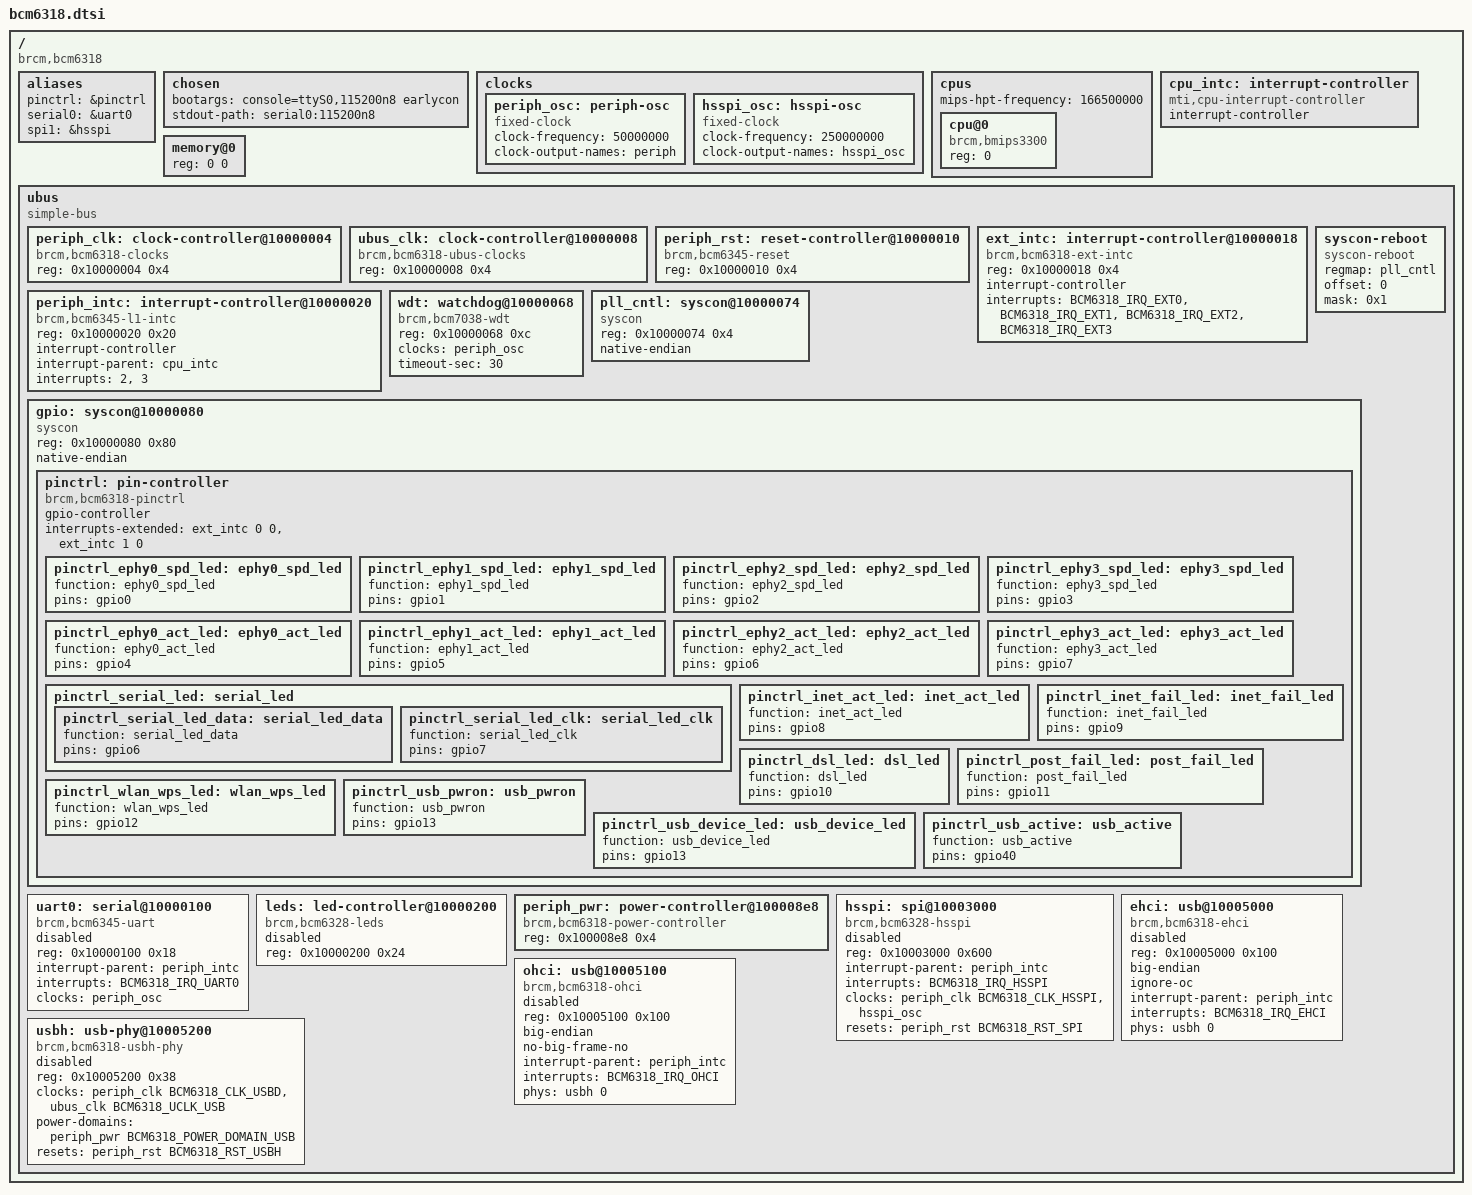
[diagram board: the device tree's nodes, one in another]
// SPDX-License-Identifier: GPL-2.0-or-later

/dts-v1/;

#include <dt-bindings/clock/bcm6318-clock.h>
#include <dt-bindings/gpio/gpio.h>
#include <dt-bindings/input/input.h>
#include <dt-bindings/interrupt-controller/bcm6318-interrupt-controller.h>
#include <dt-bindings/reset/bcm6318-reset.h>
#include <dt-bindings/soc/bcm6318-pm.h>

/ {
	#address-cells = <1>;
	#size-cells = <1>;
	compatible = "brcm,bcm6318";

	aliases {
		pinctrl = &pinctrl;
		serial0 = &uart0;
		spi1 = &hsspi;
	};

	chosen {
		bootargs = "console=ttyS0,115200n8 earlycon";
		stdout-path = "serial0:115200n8";
	};

	clocks {
		periph_osc: periph-osc {
			compatible = "fixed-clock";

			#clock-cells = <0>;

			clock-frequency = <50000000>;
			clock-output-names = "periph";
		};

		hsspi_osc: hsspi-osc {
			compatible = "fixed-clock";

			#clock-cells = <0>;

			clock-frequency = <250000000>;
			clock-output-names = "hsspi_osc";
		};
	};

	cpus {
		#address-cells = <1>;
		#size-cells = <0>;
		mips-hpt-frequency = <166500000>;

		cpu@0 {
			compatible = "brcm,bmips3300", "mips,mips4Kc";
			device_type = "cpu";
			reg = <0>;
		};
	};

	cpu_intc: interrupt-controller {
		#address-cells = <0>;
		compatible = "mti,cpu-interrupt-controller";

		interrupt-controller;
		#interrupt-cells = <1>;
	};

	memory@0 {
		device_type = "memory";
		reg = <0 0>;
	};

	ubus {
		#address-cells = <1>;
		#size-cells = <1>;

		compatible = "simple-bus";
		ranges;

		periph_clk: clock-controller@10000004 {
			compatible = "brcm,bcm6318-clocks";
			reg = <0x10000004 0x4>;
			#clock-cells = <1>;
		};

		ubus_clk: clock-controller@10000008 {
			compatible = "brcm,bcm6318-ubus-clocks";
			reg = <0x10000008 0x4>;
			#clock-cells = <1>;
		};

		periph_rst: reset-controller@10000010 {
			compatible = "brcm,bcm6345-reset";
			reg = <0x10000010 0x4>;
			#reset-cells = <1>;
		};

		ext_intc: interrupt-controller@10000018 {
			#address-cells = <1>;
			compatible = "brcm,bcm6318-ext-intc";
			reg = <0x10000018 0x4>;

			interrupt-controller;
			#interrupt-cells = <2>;

			interrupts = <BCM6318_IRQ_EXT0>,
				     <BCM6318_IRQ_EXT1>,
				     <BCM6318_IRQ_EXT2>,
				     <BCM6318_IRQ_EXT3>;
		};

		periph_intc: interrupt-controller@10000020 {
			#address-cells = <1>;
			compatible = "brcm,bcm6345-l1-intc";
			reg = <0x10000020 0x20>;

			interrupt-controller;
			#interrupt-cells = <1>;

			interrupt-parent = <&cpu_intc>;
			interrupts = <2>, <3>;
		};

		wdt: watchdog@10000068 {
			compatible = "brcm,bcm7038-wdt";
			reg = <0x10000068 0xc>;

			clocks = <&periph_osc>;

			timeout-sec = <30>;
		};

		pll_cntl: syscon@10000074 {
			compatible = "syscon";
			reg = <0x10000074 0x4>;
			native-endian;
		};

		syscon-reboot {
			compatible = "syscon-reboot";
			regmap = <&pll_cntl>;
			offset = <0>;
			mask = <0x1>;
		};

		gpio: syscon@10000080 {
			compatible = "syscon", "simple-mfd";
			reg = <0x10000080 0x80>;
			native-endian;

			pinctrl: pin-controller {
				compatible = "brcm,bcm6318-pinctrl";

				gpio-controller;
				#gpio-cells = <2>;

				interrupts-extended = <&ext_intc 0 0>,
						      <&ext_intc 1 0>;
				interrupt-names = "gpio33",
						  "gpio34";

				pinctrl_ephy0_spd_led: ephy0_spd_led {
					function = "ephy0_spd_led";
					pins = "gpio0";
				};

				pinctrl_ephy1_spd_led: ephy1_spd_led {
					function = "ephy1_spd_led";
					pins = "gpio1";
				};

				pinctrl_ephy2_spd_led: ephy2_spd_led {
					function = "ephy2_spd_led";
					pins = "gpio2";
				};

				pinctrl_ephy3_spd_led: ephy3_spd_led {
					function = "ephy3_spd_led";
					pins = "gpio3";
				};

				pinctrl_ephy0_act_led: ephy0_act_led {
					function = "ephy0_act_led";
					pins = "gpio4";
				};

				pinctrl_ephy1_act_led: ephy1_act_led {
					function = "ephy1_act_led";
					pins = "gpio5";
				};

				pinctrl_ephy2_act_led: ephy2_act_led {
					function = "ephy2_act_led";
					pins = "gpio6";
				};

				pinctrl_ephy3_act_led: ephy3_act_led {
					function = "ephy3_act_led";
					pins = "gpio7";
				};

				pinctrl_serial_led: serial_led {
					pinctrl_serial_led_data: serial_led_data {
						function = "serial_led_data";
						pins = "gpio6";
					};

					pinctrl_serial_led_clk: serial_led_clk {
						function = "serial_led_clk";
						pins = "gpio7";
					};
				};

				pinctrl_inet_act_led: inet_act_led {
					function = "inet_act_led";
					pins = "gpio8";
				};

				pinctrl_inet_fail_led: inet_fail_led {
					function = "inet_fail_led";
					pins = "gpio9";
				};

				pinctrl_dsl_led: dsl_led {
					function = "dsl_led";
					pins = "gpio10";
				};

				pinctrl_post_fail_led: post_fail_led {
					function = "post_fail_led";
					pins = "gpio11";
				};

				pinctrl_wlan_wps_led: wlan_wps_led {
					function = "wlan_wps_led";
					pins = "gpio12";
				};

				pinctrl_usb_pwron: usb_pwron {
					function = "usb_pwron";
					pins = "gpio13";
				};

				pinctrl_usb_device_led: usb_device_led {
					function = "usb_device_led";
					pins = "gpio13";
				};

				pinctrl_usb_active: usb_active {
					function = "usb_active";
					pins = "gpio40";
				};
			};
		};

		uart0: serial@10000100 {
			compatible = "brcm,bcm6345-uart";
			reg = <0x10000100 0x18>;

			interrupt-parent = <&periph_intc>;
			interrupts = <BCM6318_IRQ_UART0>;

			clocks = <&periph_osc>;
			clock-names = "periph";

			status = "disabled";
		};

		leds: led-controller@10000200 {
			#address-cells = <1>;
			#size-cells = <0>;
			compatible = "brcm,bcm6328-leds";
			reg = <0x10000200 0x24>;

			status = "disabled";
		};

		periph_pwr: power-controller@100008e8 {
			compatible = "brcm,bcm6318-power-controller";
			reg = <0x100008e8 0x4>;

			#power-domain-cells = <1>;
		};

		hsspi: spi@10003000 {
			compatible = "brcm,bcm6328-hsspi";
			reg = <0x10003000 0x600>;
			#address-cells = <1>;
			#size-cells = <0>;

			interrupt-parent = <&periph_intc>;
			interrupts = <BCM6318_IRQ_HSSPI>;

			clocks = <&periph_clk BCM6318_CLK_HSSPI>,
				 <&hsspi_osc>;
			clock-names = "hsspi",
				      "pll";

			resets = <&periph_rst BCM6318_RST_SPI>;

			status = "disabled";
		};

		ehci: usb@10005000 {
			compatible = "brcm,bcm6318-ehci", "generic-ehci";
			reg = <0x10005000 0x100>;
			big-endian;
			ignore-oc;

			interrupt-parent = <&periph_intc>;
			interrupts = <BCM6318_IRQ_EHCI>;

			phys = <&usbh 0>;
			phy-names = "usb";

			status = "disabled";
		};

		ohci: usb@10005100 {
			compatible = "brcm,bcm6318-ohci", "generic-ohci";
			reg = <0x10005100 0x100>;
			big-endian;
			no-big-frame-no;

			interrupt-parent = <&periph_intc>;
			interrupts = <BCM6318_IRQ_OHCI>;

			phys = <&usbh 0>;
			phy-names = "usb";

			status = "disabled";
		};

		usbh: usb-phy@10005200 {
			compatible = "brcm,bcm6318-usbh-phy";
			reg = <0x10005200 0x38>;

			#phy-cells = <1>;

			clocks = <&periph_clk BCM6318_CLK_USBD>,
				 <&ubus_clk BCM6318_UCLK_USB>;
			clock-names = "usbh",
				      "usb_ref";

			power-domains = <&periph_pwr BCM6318_POWER_DOMAIN_USB>;
			resets = <&periph_rst BCM6318_RST_USBH>;

			status = "disabled";
		};
	};
};
